# iorx65n register map
Registers are 8-bit, access not given, no defined reset value unless marked. A register's access mark holds for its fields unless they carry their own. Addresses are absolute; registers are grouped by the start of their names; [hi:lo] are bit positions; {n}, {i} and the like mark numbered series.

## SFR (part 7 of 7)
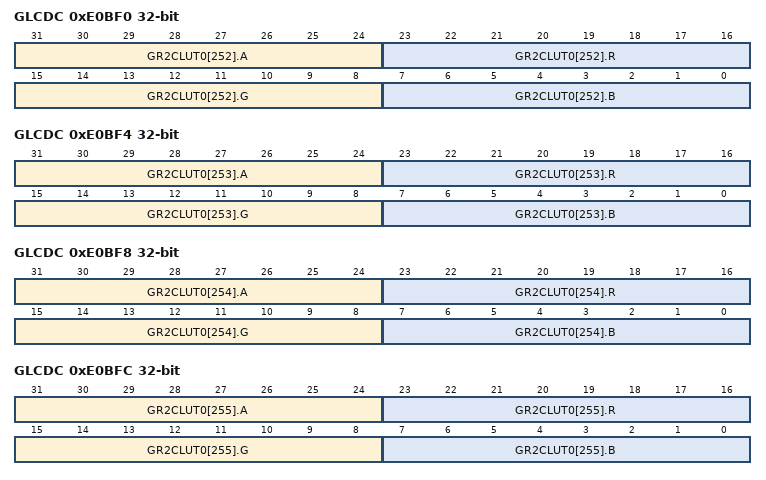
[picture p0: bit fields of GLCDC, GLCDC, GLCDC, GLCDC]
0xE0BF0 GLCDC 32-bit
  [31:24] GR2CLUT0[252].A, [23:16] GR2CLUT0[252].R, [15:8] GR2CLUT0[252].G, [7:0] GR2CLUT0[252].B
0xE0BF4 GLCDC 32-bit
  [31:24] GR2CLUT0[253].A, [23:16] GR2CLUT0[253].R, [15:8] GR2CLUT0[253].G, [7:0] GR2CLUT0[253].B
0xE0BF8 GLCDC 32-bit
  [31:24] GR2CLUT0[254].A, [23:16] GR2CLUT0[254].R, [15:8] GR2CLUT0[254].G, [7:0] GR2CLUT0[254].B
0xE0BFC GLCDC 32-bit
  [31:24] GR2CLUT0[255].A, [23:16] GR2CLUT0[255].R, [15:8] GR2CLUT0[255].G, [7:0] GR2CLUT0[255].B
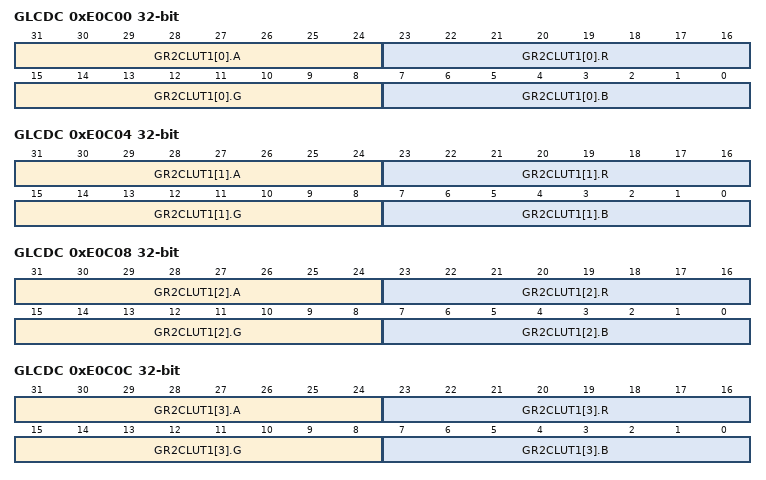
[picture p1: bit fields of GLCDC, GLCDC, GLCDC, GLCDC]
0xE0C00 GLCDC 32-bit
  [31:24] GR2CLUT1[0].A, [23:16] GR2CLUT1[0].R, [15:8] GR2CLUT1[0].G, [7:0] GR2CLUT1[0].B
0xE0C04 GLCDC 32-bit
  [31:24] GR2CLUT1[1].A, [23:16] GR2CLUT1[1].R, [15:8] GR2CLUT1[1].G, [7:0] GR2CLUT1[1].B
0xE0C08 GLCDC 32-bit
  [31:24] GR2CLUT1[2].A, [23:16] GR2CLUT1[2].R, [15:8] GR2CLUT1[2].G, [7:0] GR2CLUT1[2].B
0xE0C0C GLCDC 32-bit
  [31:24] GR2CLUT1[3].A, [23:16] GR2CLUT1[3].R, [15:8] GR2CLUT1[3].G, [7:0] GR2CLUT1[3].B
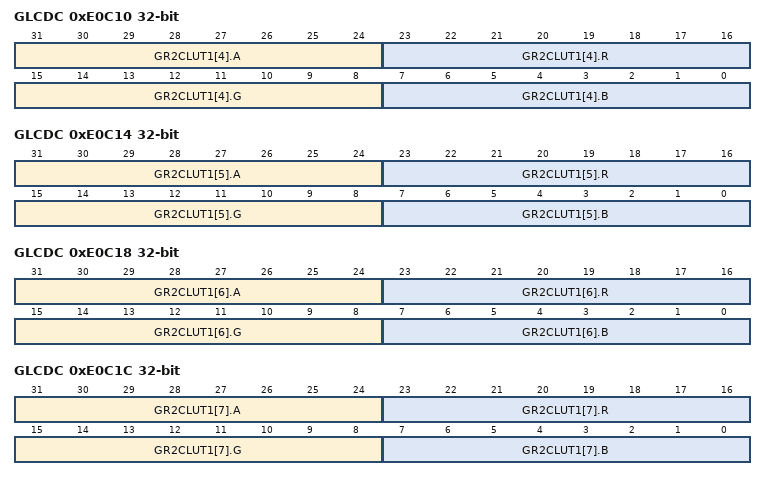
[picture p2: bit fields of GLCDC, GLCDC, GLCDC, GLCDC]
0xE0C10 GLCDC 32-bit
  [31:24] GR2CLUT1[4].A, [23:16] GR2CLUT1[4].R, [15:8] GR2CLUT1[4].G, [7:0] GR2CLUT1[4].B
0xE0C14 GLCDC 32-bit
  [31:24] GR2CLUT1[5].A, [23:16] GR2CLUT1[5].R, [15:8] GR2CLUT1[5].G, [7:0] GR2CLUT1[5].B
0xE0C18 GLCDC 32-bit
  [31:24] GR2CLUT1[6].A, [23:16] GR2CLUT1[6].R, [15:8] GR2CLUT1[6].G, [7:0] GR2CLUT1[6].B
0xE0C1C GLCDC 32-bit
  [31:24] GR2CLUT1[7].A, [23:16] GR2CLUT1[7].R, [15:8] GR2CLUT1[7].G, [7:0] GR2CLUT1[7].B
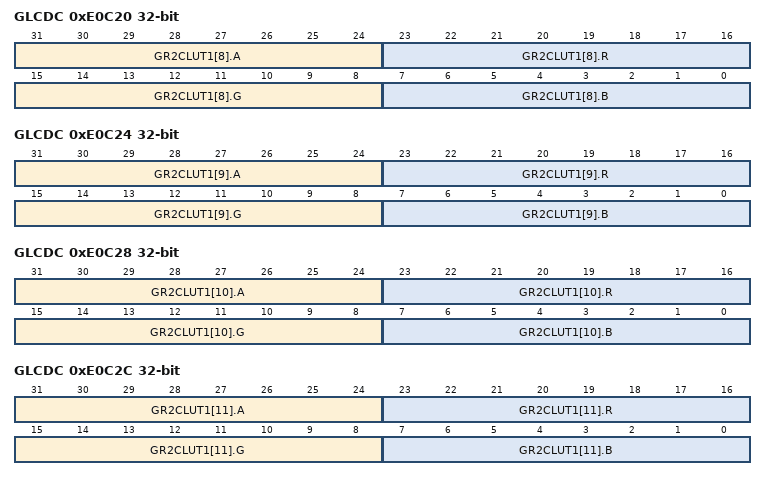
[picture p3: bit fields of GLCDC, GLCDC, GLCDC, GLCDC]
0xE0C20 GLCDC 32-bit
  [31:24] GR2CLUT1[8].A, [23:16] GR2CLUT1[8].R, [15:8] GR2CLUT1[8].G, [7:0] GR2CLUT1[8].B
0xE0C24 GLCDC 32-bit
  [31:24] GR2CLUT1[9].A, [23:16] GR2CLUT1[9].R, [15:8] GR2CLUT1[9].G, [7:0] GR2CLUT1[9].B
0xE0C28 GLCDC 32-bit
  [31:24] GR2CLUT1[10].A, [23:16] GR2CLUT1[10].R, [15:8] GR2CLUT1[10].G, [7:0] GR2CLUT1[10].B
0xE0C2C GLCDC 32-bit
  [31:24] GR2CLUT1[11].A, [23:16] GR2CLUT1[11].R, [15:8] GR2CLUT1[11].G, [7:0] GR2CLUT1[11].B
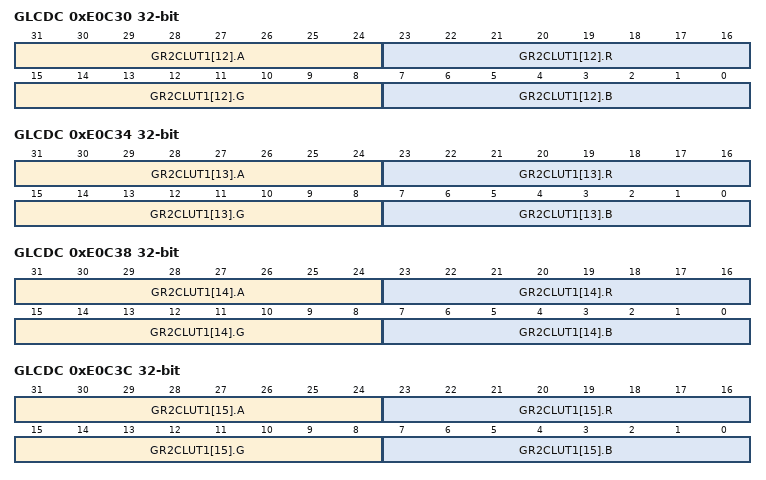
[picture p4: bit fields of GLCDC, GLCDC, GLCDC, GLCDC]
0xE0C30 GLCDC 32-bit
  [31:24] GR2CLUT1[12].A, [23:16] GR2CLUT1[12].R, [15:8] GR2CLUT1[12].G, [7:0] GR2CLUT1[12].B
0xE0C34 GLCDC 32-bit
  [31:24] GR2CLUT1[13].A, [23:16] GR2CLUT1[13].R, [15:8] GR2CLUT1[13].G, [7:0] GR2CLUT1[13].B
0xE0C38 GLCDC 32-bit
  [31:24] GR2CLUT1[14].A, [23:16] GR2CLUT1[14].R, [15:8] GR2CLUT1[14].G, [7:0] GR2CLUT1[14].B
0xE0C3C GLCDC 32-bit
  [31:24] GR2CLUT1[15].A, [23:16] GR2CLUT1[15].R, [15:8] GR2CLUT1[15].G, [7:0] GR2CLUT1[15].B
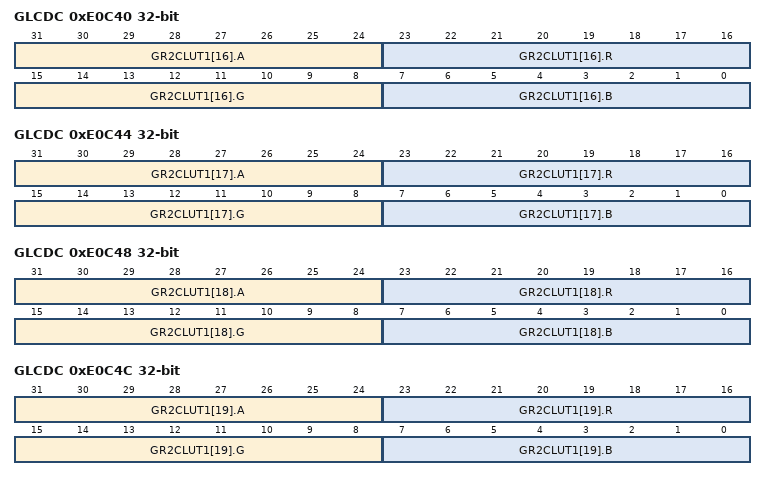
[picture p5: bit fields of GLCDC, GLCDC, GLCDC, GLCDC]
0xE0C40 GLCDC 32-bit
  [31:24] GR2CLUT1[16].A, [23:16] GR2CLUT1[16].R, [15:8] GR2CLUT1[16].G, [7:0] GR2CLUT1[16].B
0xE0C44 GLCDC 32-bit
  [31:24] GR2CLUT1[17].A, [23:16] GR2CLUT1[17].R, [15:8] GR2CLUT1[17].G, [7:0] GR2CLUT1[17].B
0xE0C48 GLCDC 32-bit
  [31:24] GR2CLUT1[18].A, [23:16] GR2CLUT1[18].R, [15:8] GR2CLUT1[18].G, [7:0] GR2CLUT1[18].B
0xE0C4C GLCDC 32-bit
  [31:24] GR2CLUT1[19].A, [23:16] GR2CLUT1[19].R, [15:8] GR2CLUT1[19].G, [7:0] GR2CLUT1[19].B
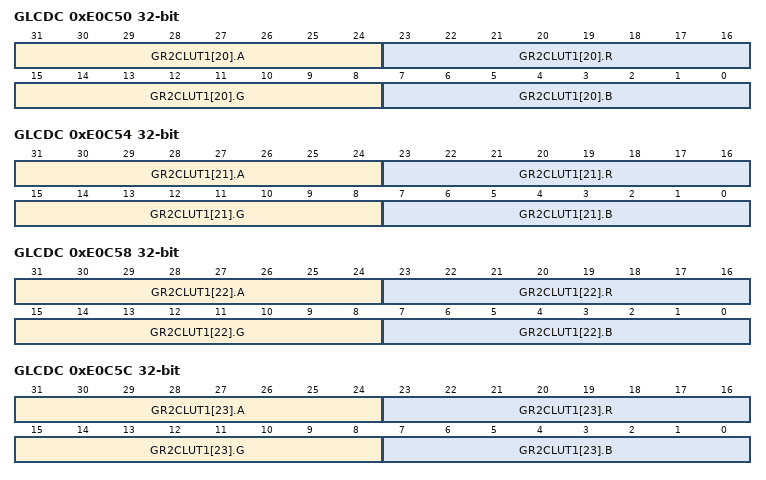
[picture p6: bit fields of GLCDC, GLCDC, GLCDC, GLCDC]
0xE0C50 GLCDC 32-bit
  [31:24] GR2CLUT1[20].A, [23:16] GR2CLUT1[20].R, [15:8] GR2CLUT1[20].G, [7:0] GR2CLUT1[20].B
0xE0C54 GLCDC 32-bit
  [31:24] GR2CLUT1[21].A, [23:16] GR2CLUT1[21].R, [15:8] GR2CLUT1[21].G, [7:0] GR2CLUT1[21].B
0xE0C58 GLCDC 32-bit
  [31:24] GR2CLUT1[22].A, [23:16] GR2CLUT1[22].R, [15:8] GR2CLUT1[22].G, [7:0] GR2CLUT1[22].B
0xE0C5C GLCDC 32-bit
  [31:24] GR2CLUT1[23].A, [23:16] GR2CLUT1[23].R, [15:8] GR2CLUT1[23].G, [7:0] GR2CLUT1[23].B
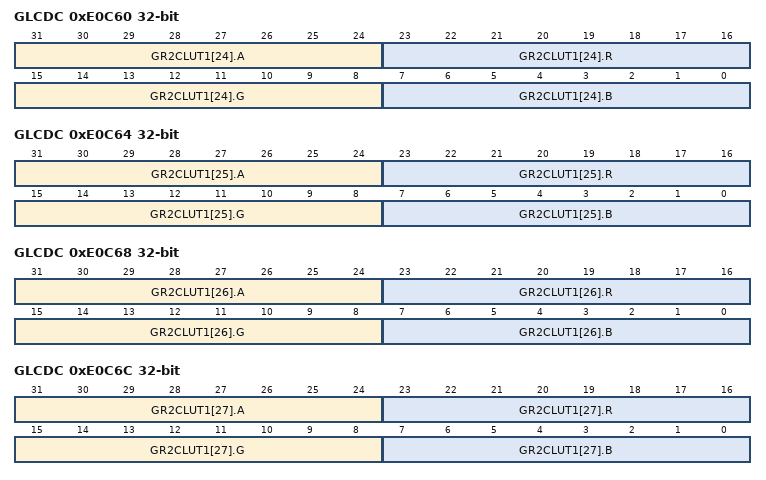
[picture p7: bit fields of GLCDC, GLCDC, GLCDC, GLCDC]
0xE0C60 GLCDC 32-bit
  [31:24] GR2CLUT1[24].A, [23:16] GR2CLUT1[24].R, [15:8] GR2CLUT1[24].G, [7:0] GR2CLUT1[24].B
0xE0C64 GLCDC 32-bit
  [31:24] GR2CLUT1[25].A, [23:16] GR2CLUT1[25].R, [15:8] GR2CLUT1[25].G, [7:0] GR2CLUT1[25].B
0xE0C68 GLCDC 32-bit
  [31:24] GR2CLUT1[26].A, [23:16] GR2CLUT1[26].R, [15:8] GR2CLUT1[26].G, [7:0] GR2CLUT1[26].B
0xE0C6C GLCDC 32-bit
  [31:24] GR2CLUT1[27].A, [23:16] GR2CLUT1[27].R, [15:8] GR2CLUT1[27].G, [7:0] GR2CLUT1[27].B
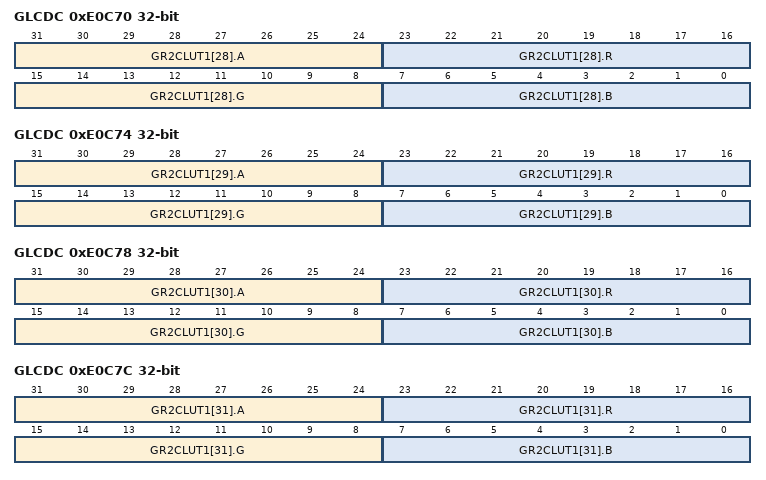
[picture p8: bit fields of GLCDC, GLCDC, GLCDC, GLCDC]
0xE0C70 GLCDC 32-bit
  [31:24] GR2CLUT1[28].A, [23:16] GR2CLUT1[28].R, [15:8] GR2CLUT1[28].G, [7:0] GR2CLUT1[28].B
0xE0C74 GLCDC 32-bit
  [31:24] GR2CLUT1[29].A, [23:16] GR2CLUT1[29].R, [15:8] GR2CLUT1[29].G, [7:0] GR2CLUT1[29].B
0xE0C78 GLCDC 32-bit
  [31:24] GR2CLUT1[30].A, [23:16] GR2CLUT1[30].R, [15:8] GR2CLUT1[30].G, [7:0] GR2CLUT1[30].B
0xE0C7C GLCDC 32-bit
  [31:24] GR2CLUT1[31].A, [23:16] GR2CLUT1[31].R, [15:8] GR2CLUT1[31].G, [7:0] GR2CLUT1[31].B
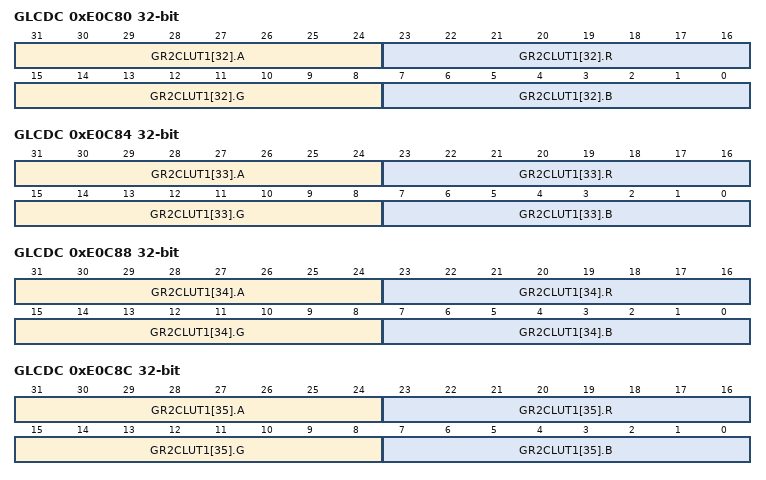
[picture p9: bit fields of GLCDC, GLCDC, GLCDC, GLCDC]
0xE0C80 GLCDC 32-bit
  [31:24] GR2CLUT1[32].A, [23:16] GR2CLUT1[32].R, [15:8] GR2CLUT1[32].G, [7:0] GR2CLUT1[32].B
0xE0C84 GLCDC 32-bit
  [31:24] GR2CLUT1[33].A, [23:16] GR2CLUT1[33].R, [15:8] GR2CLUT1[33].G, [7:0] GR2CLUT1[33].B
0xE0C88 GLCDC 32-bit
  [31:24] GR2CLUT1[34].A, [23:16] GR2CLUT1[34].R, [15:8] GR2CLUT1[34].G, [7:0] GR2CLUT1[34].B
0xE0C8C GLCDC 32-bit
  [31:24] GR2CLUT1[35].A, [23:16] GR2CLUT1[35].R, [15:8] GR2CLUT1[35].G, [7:0] GR2CLUT1[35].B
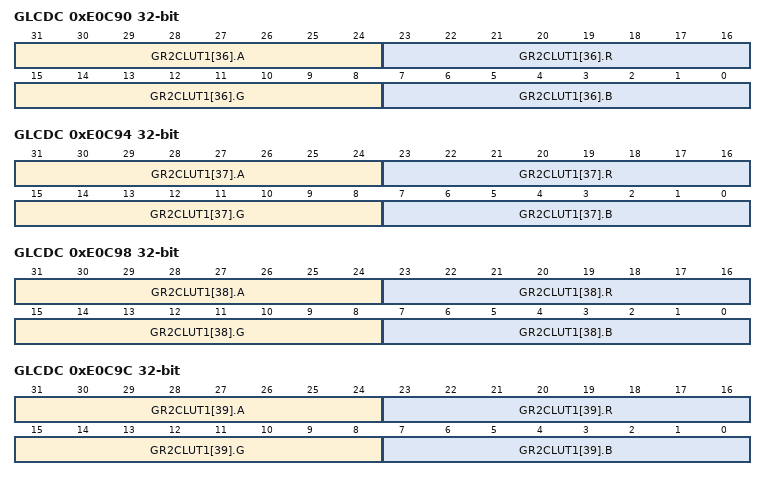
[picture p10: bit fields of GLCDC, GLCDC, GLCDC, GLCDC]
0xE0C90 GLCDC 32-bit
  [31:24] GR2CLUT1[36].A, [23:16] GR2CLUT1[36].R, [15:8] GR2CLUT1[36].G, [7:0] GR2CLUT1[36].B
0xE0C94 GLCDC 32-bit
  [31:24] GR2CLUT1[37].A, [23:16] GR2CLUT1[37].R, [15:8] GR2CLUT1[37].G, [7:0] GR2CLUT1[37].B
0xE0C98 GLCDC 32-bit
  [31:24] GR2CLUT1[38].A, [23:16] GR2CLUT1[38].R, [15:8] GR2CLUT1[38].G, [7:0] GR2CLUT1[38].B
0xE0C9C GLCDC 32-bit
  [31:24] GR2CLUT1[39].A, [23:16] GR2CLUT1[39].R, [15:8] GR2CLUT1[39].G, [7:0] GR2CLUT1[39].B
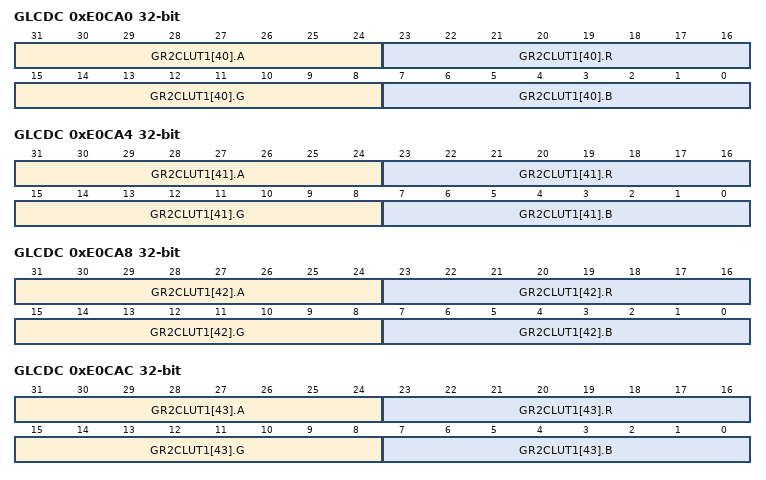
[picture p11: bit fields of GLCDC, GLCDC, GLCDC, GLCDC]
0xE0CA0 GLCDC 32-bit
  [31:24] GR2CLUT1[40].A, [23:16] GR2CLUT1[40].R, [15:8] GR2CLUT1[40].G, [7:0] GR2CLUT1[40].B
0xE0CA4 GLCDC 32-bit
  [31:24] GR2CLUT1[41].A, [23:16] GR2CLUT1[41].R, [15:8] GR2CLUT1[41].G, [7:0] GR2CLUT1[41].B
0xE0CA8 GLCDC 32-bit
  [31:24] GR2CLUT1[42].A, [23:16] GR2CLUT1[42].R, [15:8] GR2CLUT1[42].G, [7:0] GR2CLUT1[42].B
0xE0CAC GLCDC 32-bit
  [31:24] GR2CLUT1[43].A, [23:16] GR2CLUT1[43].R, [15:8] GR2CLUT1[43].G, [7:0] GR2CLUT1[43].B
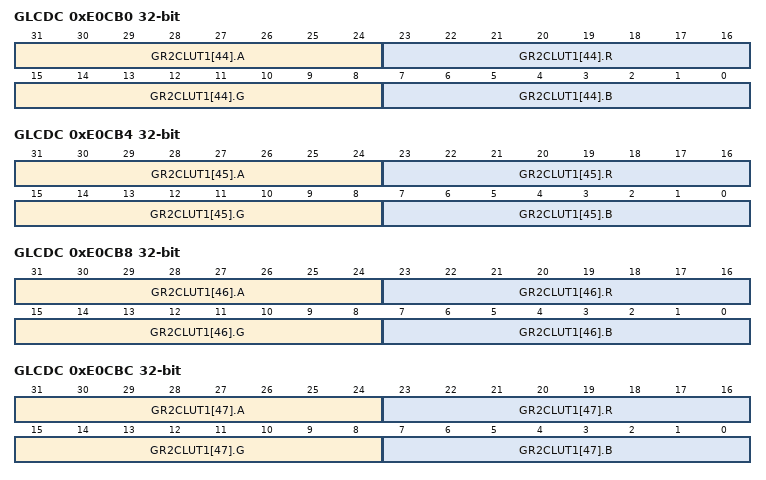
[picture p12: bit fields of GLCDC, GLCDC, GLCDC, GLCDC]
0xE0CB0 GLCDC 32-bit
  [31:24] GR2CLUT1[44].A, [23:16] GR2CLUT1[44].R, [15:8] GR2CLUT1[44].G, [7:0] GR2CLUT1[44].B
0xE0CB4 GLCDC 32-bit
  [31:24] GR2CLUT1[45].A, [23:16] GR2CLUT1[45].R, [15:8] GR2CLUT1[45].G, [7:0] GR2CLUT1[45].B
0xE0CB8 GLCDC 32-bit
  [31:24] GR2CLUT1[46].A, [23:16] GR2CLUT1[46].R, [15:8] GR2CLUT1[46].G, [7:0] GR2CLUT1[46].B
0xE0CBC GLCDC 32-bit
  [31:24] GR2CLUT1[47].A, [23:16] GR2CLUT1[47].R, [15:8] GR2CLUT1[47].G, [7:0] GR2CLUT1[47].B
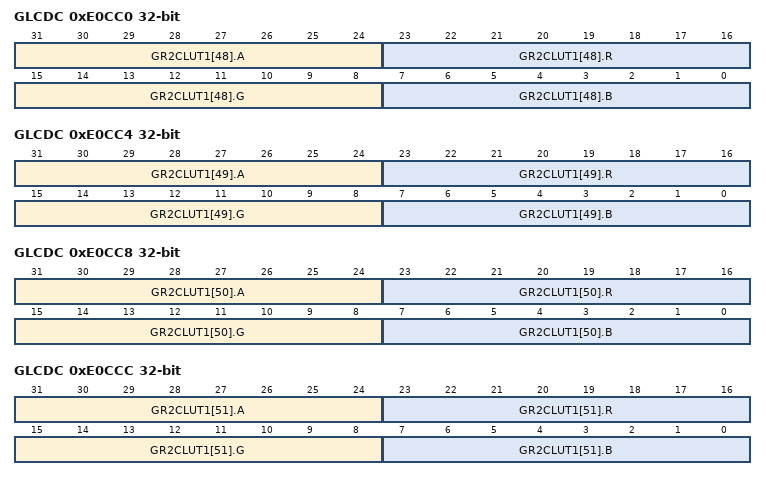
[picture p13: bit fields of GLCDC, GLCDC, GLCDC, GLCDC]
0xE0CC0 GLCDC 32-bit
  [31:24] GR2CLUT1[48].A, [23:16] GR2CLUT1[48].R, [15:8] GR2CLUT1[48].G, [7:0] GR2CLUT1[48].B
0xE0CC4 GLCDC 32-bit
  [31:24] GR2CLUT1[49].A, [23:16] GR2CLUT1[49].R, [15:8] GR2CLUT1[49].G, [7:0] GR2CLUT1[49].B
0xE0CC8 GLCDC 32-bit
  [31:24] GR2CLUT1[50].A, [23:16] GR2CLUT1[50].R, [15:8] GR2CLUT1[50].G, [7:0] GR2CLUT1[50].B
0xE0CCC GLCDC 32-bit
  [31:24] GR2CLUT1[51].A, [23:16] GR2CLUT1[51].R, [15:8] GR2CLUT1[51].G, [7:0] GR2CLUT1[51].B
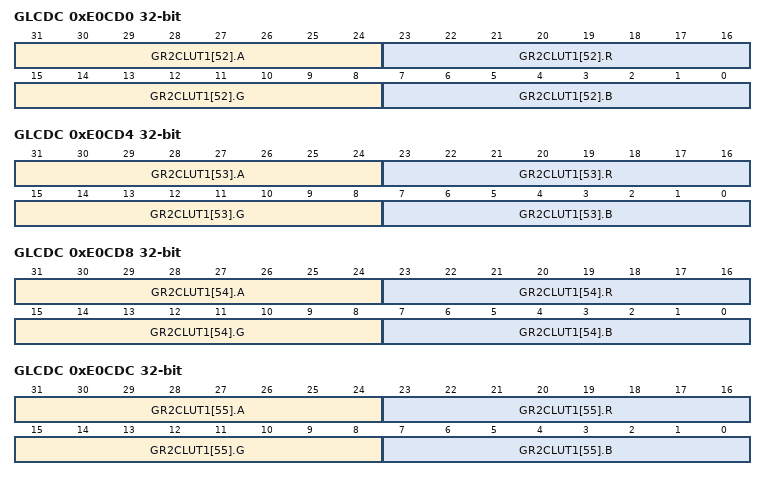
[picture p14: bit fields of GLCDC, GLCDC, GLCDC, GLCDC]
0xE0CD0 GLCDC 32-bit
  [31:24] GR2CLUT1[52].A, [23:16] GR2CLUT1[52].R, [15:8] GR2CLUT1[52].G, [7:0] GR2CLUT1[52].B
0xE0CD4 GLCDC 32-bit
  [31:24] GR2CLUT1[53].A, [23:16] GR2CLUT1[53].R, [15:8] GR2CLUT1[53].G, [7:0] GR2CLUT1[53].B
0xE0CD8 GLCDC 32-bit
  [31:24] GR2CLUT1[54].A, [23:16] GR2CLUT1[54].R, [15:8] GR2CLUT1[54].G, [7:0] GR2CLUT1[54].B
0xE0CDC GLCDC 32-bit
  [31:24] GR2CLUT1[55].A, [23:16] GR2CLUT1[55].R, [15:8] GR2CLUT1[55].G, [7:0] GR2CLUT1[55].B
0xE0CE0 GLCDC 32-bit
  [31:24] GR2CLUT1[56].A, [23:16] GR2CLUT1[56].R, [15:8] GR2CLUT1[56].G, [7:0] GR2CLUT1[56].B
0xE0CE4 GLCDC 32-bit
  [31:24] GR2CLUT1[57].A, [23:16] GR2CLUT1[57].R, [15:8] GR2CLUT1[57].G, [7:0] GR2CLUT1[57].B
0xE0CE8 GLCDC 32-bit
  [31:24] GR2CLUT1[58].A, [23:16] GR2CLUT1[58].R, [15:8] GR2CLUT1[58].G, [7:0] GR2CLUT1[58].B
0xE0CEC GLCDC 32-bit
  [31:24] GR2CLUT1[59].A, [23:16] GR2CLUT1[59].R, [15:8] GR2CLUT1[59].G, [7:0] GR2CLUT1[59].B
0xE0CF0 GLCDC 32-bit
  [31:24] GR2CLUT1[60].A, [23:16] GR2CLUT1[60].R, [15:8] GR2CLUT1[60].G, [7:0] GR2CLUT1[60].B
0xE0CF4 GLCDC 32-bit
  [31:24] GR2CLUT1[61].A, [23:16] GR2CLUT1[61].R, [15:8] GR2CLUT1[61].G, [7:0] GR2CLUT1[61].B
0xE0CF8 GLCDC 32-bit
  [31:24] GR2CLUT1[62].A, [23:16] GR2CLUT1[62].R, [15:8] GR2CLUT1[62].G, [7:0] GR2CLUT1[62].B
0xE0CFC GLCDC 32-bit
  [31:24] GR2CLUT1[63].A, [23:16] GR2CLUT1[63].R, [15:8] GR2CLUT1[63].G, [7:0] GR2CLUT1[63].B
0xE0D00 GLCDC 32-bit
  [31:24] GR2CLUT1[64].A, [23:16] GR2CLUT1[64].R, [15:8] GR2CLUT1[64].G, [7:0] GR2CLUT1[64].B
0xE0D04 GLCDC 32-bit
  [31:24] GR2CLUT1[65].A, [23:16] GR2CLUT1[65].R, [15:8] GR2CLUT1[65].G, [7:0] GR2CLUT1[65].B
0xE0D08 GLCDC 32-bit
  [31:24] GR2CLUT1[66].A, [23:16] GR2CLUT1[66].R, [15:8] GR2CLUT1[66].G, [7:0] GR2CLUT1[66].B
0xE0D0C GLCDC 32-bit
  [31:24] GR2CLUT1[67].A, [23:16] GR2CLUT1[67].R, [15:8] GR2CLUT1[67].G, [7:0] GR2CLUT1[67].B
0xE0D10 GLCDC 32-bit
  [31:24] GR2CLUT1[68].A, [23:16] GR2CLUT1[68].R, [15:8] GR2CLUT1[68].G, [7:0] GR2CLUT1[68].B
0xE0D14 GLCDC 32-bit
  [31:24] GR2CLUT1[69].A, [23:16] GR2CLUT1[69].R, [15:8] GR2CLUT1[69].G, [7:0] GR2CLUT1[69].B
0xE0D18 GLCDC 32-bit
  [31:24] GR2CLUT1[70].A, [23:16] GR2CLUT1[70].R, [15:8] GR2CLUT1[70].G, [7:0] GR2CLUT1[70].B
0xE0D1C GLCDC 32-bit
  [31:24] GR2CLUT1[71].A, [23:16] GR2CLUT1[71].R, [15:8] GR2CLUT1[71].G, [7:0] GR2CLUT1[71].B
0xE0D20 GLCDC 32-bit
  [31:24] GR2CLUT1[72].A, [23:16] GR2CLUT1[72].R, [15:8] GR2CLUT1[72].G, [7:0] GR2CLUT1[72].B
0xE0D24 GLCDC 32-bit
  [31:24] GR2CLUT1[73].A, [23:16] GR2CLUT1[73].R, [15:8] GR2CLUT1[73].G, [7:0] GR2CLUT1[73].B
0xE0D28 GLCDC 32-bit
  [31:24] GR2CLUT1[74].A, [23:16] GR2CLUT1[74].R, [15:8] GR2CLUT1[74].G, [7:0] GR2CLUT1[74].B
0xE0D2C GLCDC 32-bit
  [31:24] GR2CLUT1[75].A, [23:16] GR2CLUT1[75].R, [15:8] GR2CLUT1[75].G, [7:0] GR2CLUT1[75].B
0xE0D30 GLCDC 32-bit
  [31:24] GR2CLUT1[76].A, [23:16] GR2CLUT1[76].R, [15:8] GR2CLUT1[76].G, [7:0] GR2CLUT1[76].B
0xE0D34 GLCDC 32-bit
  [31:24] GR2CLUT1[77].A, [23:16] GR2CLUT1[77].R, [15:8] GR2CLUT1[77].G, [7:0] GR2CLUT1[77].B
0xE0D38 GLCDC 32-bit
  [31:24] GR2CLUT1[78].A, [23:16] GR2CLUT1[78].R, [15:8] GR2CLUT1[78].G, [7:0] GR2CLUT1[78].B
0xE0D3C GLCDC 32-bit
  [31:24] GR2CLUT1[79].A, [23:16] GR2CLUT1[79].R, [15:8] GR2CLUT1[79].G, [7:0] GR2CLUT1[79].B
0xE0D40 GLCDC 32-bit
  [31:24] GR2CLUT1[80].A, [23:16] GR2CLUT1[80].R, [15:8] GR2CLUT1[80].G, [7:0] GR2CLUT1[80].B
0xE0D44 GLCDC 32-bit
  [31:24] GR2CLUT1[81].A, [23:16] GR2CLUT1[81].R, [15:8] GR2CLUT1[81].G, [7:0] GR2CLUT1[81].B
0xE0D48 GLCDC 32-bit
  [31:24] GR2CLUT1[82].A, [23:16] GR2CLUT1[82].R, [15:8] GR2CLUT1[82].G, [7:0] GR2CLUT1[82].B
0xE0D4C GLCDC 32-bit
  [31:24] GR2CLUT1[83].A, [23:16] GR2CLUT1[83].R, [15:8] GR2CLUT1[83].G, [7:0] GR2CLUT1[83].B
0xE0D50 GLCDC 32-bit
  [31:24] GR2CLUT1[84].A, [23:16] GR2CLUT1[84].R, [15:8] GR2CLUT1[84].G, [7:0] GR2CLUT1[84].B
0xE0D54 GLCDC 32-bit
  [31:24] GR2CLUT1[85].A, [23:16] GR2CLUT1[85].R, [15:8] GR2CLUT1[85].G, [7:0] GR2CLUT1[85].B
0xE0D58 GLCDC 32-bit
  [31:24] GR2CLUT1[86].A, [23:16] GR2CLUT1[86].R, [15:8] GR2CLUT1[86].G, [7:0] GR2CLUT1[86].B
0xE0D5C GLCDC 32-bit
  [31:24] GR2CLUT1[87].A, [23:16] GR2CLUT1[87].R, [15:8] GR2CLUT1[87].G, [7:0] GR2CLUT1[87].B
0xE0D60 GLCDC 32-bit
  [31:24] GR2CLUT1[88].A, [23:16] GR2CLUT1[88].R, [15:8] GR2CLUT1[88].G, [7:0] GR2CLUT1[88].B
0xE0D64 GLCDC 32-bit
  [31:24] GR2CLUT1[89].A, [23:16] GR2CLUT1[89].R, [15:8] GR2CLUT1[89].G, [7:0] GR2CLUT1[89].B
0xE0D68 GLCDC 32-bit
  [31:24] GR2CLUT1[90].A, [23:16] GR2CLUT1[90].R, [15:8] GR2CLUT1[90].G, [7:0] GR2CLUT1[90].B
0xE0D6C GLCDC 32-bit
  [31:24] GR2CLUT1[91].A, [23:16] GR2CLUT1[91].R, [15:8] GR2CLUT1[91].G, [7:0] GR2CLUT1[91].B
0xE0D70 GLCDC 32-bit
  [31:24] GR2CLUT1[92].A, [23:16] GR2CLUT1[92].R, [15:8] GR2CLUT1[92].G, [7:0] GR2CLUT1[92].B
0xE0D74 GLCDC 32-bit
  [31:24] GR2CLUT1[93].A, [23:16] GR2CLUT1[93].R, [15:8] GR2CLUT1[93].G, [7:0] GR2CLUT1[93].B
0xE0D78 GLCDC 32-bit
  [31:24] GR2CLUT1[94].A, [23:16] GR2CLUT1[94].R, [15:8] GR2CLUT1[94].G, [7:0] GR2CLUT1[94].B
0xE0D7C GLCDC 32-bit
  [31:24] GR2CLUT1[95].A, [23:16] GR2CLUT1[95].R, [15:8] GR2CLUT1[95].G, [7:0] GR2CLUT1[95].B
0xE0D80 GLCDC 32-bit
  [31:24] GR2CLUT1[96].A, [23:16] GR2CLUT1[96].R, [15:8] GR2CLUT1[96].G, [7:0] GR2CLUT1[96].B
0xE0D84 GLCDC 32-bit
  [31:24] GR2CLUT1[97].A, [23:16] GR2CLUT1[97].R, [15:8] GR2CLUT1[97].G, [7:0] GR2CLUT1[97].B
0xE0D88 GLCDC 32-bit
  [31:24] GR2CLUT1[98].A, [23:16] GR2CLUT1[98].R, [15:8] GR2CLUT1[98].G, [7:0] GR2CLUT1[98].B
0xE0D8C GLCDC 32-bit
  [31:24] GR2CLUT1[99].A, [23:16] GR2CLUT1[99].R, [15:8] GR2CLUT1[99].G, [7:0] GR2CLUT1[99].B
0xE0D90 GLCDC 32-bit
  [31:24] GR2CLUT1[100].A, [23:16] GR2CLUT1[100].R, [15:8] GR2CLUT1[100].G, [7:0] GR2CLUT1[100].B
0xE0D94 GLCDC 32-bit
  [31:24] GR2CLUT1[101].A, [23:16] GR2CLUT1[101].R, [15:8] GR2CLUT1[101].G, [7:0] GR2CLUT1[101].B
0xE0D98 GLCDC 32-bit
  [31:24] GR2CLUT1[102].A, [23:16] GR2CLUT1[102].R, [15:8] GR2CLUT1[102].G, [7:0] GR2CLUT1[102].B
0xE0D9C GLCDC 32-bit
  [31:24] GR2CLUT1[103].A, [23:16] GR2CLUT1[103].R, [15:8] GR2CLUT1[103].G, [7:0] GR2CLUT1[103].B
0xE0DA0 GLCDC 32-bit
  [31:24] GR2CLUT1[104].A, [23:16] GR2CLUT1[104].R, [15:8] GR2CLUT1[104].G, [7:0] GR2CLUT1[104].B
0xE0DA4 GLCDC 32-bit
  [31:24] GR2CLUT1[105].A, [23:16] GR2CLUT1[105].R, [15:8] GR2CLUT1[105].G, [7:0] GR2CLUT1[105].B
0xE0DA8 GLCDC 32-bit
  [31:24] GR2CLUT1[106].A, [23:16] GR2CLUT1[106].R, [15:8] GR2CLUT1[106].G, [7:0] GR2CLUT1[106].B
0xE0DAC GLCDC 32-bit
  [31:24] GR2CLUT1[107].A, [23:16] GR2CLUT1[107].R, [15:8] GR2CLUT1[107].G, [7:0] GR2CLUT1[107].B
0xE0DB0 GLCDC 32-bit
  [31:24] GR2CLUT1[108].A, [23:16] GR2CLUT1[108].R, [15:8] GR2CLUT1[108].G, [7:0] GR2CLUT1[108].B
0xE0DB4 GLCDC 32-bit
  [31:24] GR2CLUT1[109].A, [23:16] GR2CLUT1[109].R, [15:8] GR2CLUT1[109].G, [7:0] GR2CLUT1[109].B
0xE0DB8 GLCDC 32-bit
  [31:24] GR2CLUT1[110].A, [23:16] GR2CLUT1[110].R, [15:8] GR2CLUT1[110].G, [7:0] GR2CLUT1[110].B
0xE0DBC GLCDC 32-bit
  [31:24] GR2CLUT1[111].A, [23:16] GR2CLUT1[111].R, [15:8] GR2CLUT1[111].G, [7:0] GR2CLUT1[111].B
0xE0DC0 GLCDC 32-bit
  [31:24] GR2CLUT1[112].A, [23:16] GR2CLUT1[112].R, [15:8] GR2CLUT1[112].G, [7:0] GR2CLUT1[112].B
0xE0DC4 GLCDC 32-bit
  [31:24] GR2CLUT1[113].A, [23:16] GR2CLUT1[113].R, [15:8] GR2CLUT1[113].G, [7:0] GR2CLUT1[113].B
0xE0DC8 GLCDC 32-bit
  [31:24] GR2CLUT1[114].A, [23:16] GR2CLUT1[114].R, [15:8] GR2CLUT1[114].G, [7:0] GR2CLUT1[114].B
0xE0DCC GLCDC 32-bit
  [31:24] GR2CLUT1[115].A, [23:16] GR2CLUT1[115].R, [15:8] GR2CLUT1[115].G, [7:0] GR2CLUT1[115].B
0xE0DD0 GLCDC 32-bit
  [31:24] GR2CLUT1[116].A, [23:16] GR2CLUT1[116].R, [15:8] GR2CLUT1[116].G, [7:0] GR2CLUT1[116].B
0xE0DD4 GLCDC 32-bit
  [31:24] GR2CLUT1[117].A, [23:16] GR2CLUT1[117].R, [15:8] GR2CLUT1[117].G, [7:0] GR2CLUT1[117].B
0xE0DD8 GLCDC 32-bit
  [31:24] GR2CLUT1[118].A, [23:16] GR2CLUT1[118].R, [15:8] GR2CLUT1[118].G, [7:0] GR2CLUT1[118].B
0xE0DDC GLCDC 32-bit
  [31:24] GR2CLUT1[119].A, [23:16] GR2CLUT1[119].R, [15:8] GR2CLUT1[119].G, [7:0] GR2CLUT1[119].B
0xE0DE0 GLCDC 32-bit
  [31:24] GR2CLUT1[120].A, [23:16] GR2CLUT1[120].R, [15:8] GR2CLUT1[120].G, [7:0] GR2CLUT1[120].B
0xE0DE4 GLCDC 32-bit
  [31:24] GR2CLUT1[121].A, [23:16] GR2CLUT1[121].R, [15:8] GR2CLUT1[121].G, [7:0] GR2CLUT1[121].B
0xE0DE8 GLCDC 32-bit
  [31:24] GR2CLUT1[122].A, [23:16] GR2CLUT1[122].R, [15:8] GR2CLUT1[122].G, [7:0] GR2CLUT1[122].B
0xE0DEC GLCDC 32-bit
  [31:24] GR2CLUT1[123].A, [23:16] GR2CLUT1[123].R, [15:8] GR2CLUT1[123].G, [7:0] GR2CLUT1[123].B
0xE0DF0 GLCDC 32-bit
  [31:24] GR2CLUT1[124].A, [23:16] GR2CLUT1[124].R, [15:8] GR2CLUT1[124].G, [7:0] GR2CLUT1[124].B
0xE0DF4 GLCDC 32-bit
  [31:24] GR2CLUT1[125].A, [23:16] GR2CLUT1[125].R, [15:8] GR2CLUT1[125].G, [7:0] GR2CLUT1[125].B
0xE0DF8 GLCDC 32-bit
  [31:24] GR2CLUT1[126].A, [23:16] GR2CLUT1[126].R, [15:8] GR2CLUT1[126].G, [7:0] GR2CLUT1[126].B
0xE0DFC GLCDC 32-bit
  [31:24] GR2CLUT1[127].A, [23:16] GR2CLUT1[127].R, [15:8] GR2CLUT1[127].G, [7:0] GR2CLUT1[127].B
0xE0E00 GLCDC 32-bit
  [31:24] GR2CLUT1[128].A, [23:16] GR2CLUT1[128].R, [15:8] GR2CLUT1[128].G, [7:0] GR2CLUT1[128].B
0xE0E04 GLCDC 32-bit
  [31:24] GR2CLUT1[129].A, [23:16] GR2CLUT1[129].R, [15:8] GR2CLUT1[129].G, [7:0] GR2CLUT1[129].B
0xE0E08 GLCDC 32-bit
  [31:24] GR2CLUT1[130].A, [23:16] GR2CLUT1[130].R, [15:8] GR2CLUT1[130].G, [7:0] GR2CLUT1[130].B
0xE0E0C GLCDC 32-bit
  [31:24] GR2CLUT1[131].A, [23:16] GR2CLUT1[131].R, [15:8] GR2CLUT1[131].G, [7:0] GR2CLUT1[131].B
0xE0E10 GLCDC 32-bit
  [31:24] GR2CLUT1[132].A, [23:16] GR2CLUT1[132].R, [15:8] GR2CLUT1[132].G, [7:0] GR2CLUT1[132].B
0xE0E14 GLCDC 32-bit
  [31:24] GR2CLUT1[133].A, [23:16] GR2CLUT1[133].R, [15:8] GR2CLUT1[133].G, [7:0] GR2CLUT1[133].B
0xE0E18 GLCDC 32-bit
  [31:24] GR2CLUT1[134].A, [23:16] GR2CLUT1[134].R, [15:8] GR2CLUT1[134].G, [7:0] GR2CLUT1[134].B
0xE0E1C GLCDC 32-bit
  [31:24] GR2CLUT1[135].A, [23:16] GR2CLUT1[135].R, [15:8] GR2CLUT1[135].G, [7:0] GR2CLUT1[135].B
0xE0E20 GLCDC 32-bit
  [31:24] GR2CLUT1[136].A, [23:16] GR2CLUT1[136].R, [15:8] GR2CLUT1[136].G, [7:0] GR2CLUT1[136].B
0xE0E24 GLCDC 32-bit
  [31:24] GR2CLUT1[137].A, [23:16] GR2CLUT1[137].R, [15:8] GR2CLUT1[137].G, [7:0] GR2CLUT1[137].B
0xE0E28 GLCDC 32-bit
  [31:24] GR2CLUT1[138].A, [23:16] GR2CLUT1[138].R, [15:8] GR2CLUT1[138].G, [7:0] GR2CLUT1[138].B
0xE0E2C GLCDC 32-bit
  [31:24] GR2CLUT1[139].A, [23:16] GR2CLUT1[139].R, [15:8] GR2CLUT1[139].G, [7:0] GR2CLUT1[139].B
0xE0E30 GLCDC 32-bit
  [31:24] GR2CLUT1[140].A, [23:16] GR2CLUT1[140].R, [15:8] GR2CLUT1[140].G, [7:0] GR2CLUT1[140].B
0xE0E34 GLCDC 32-bit
  [31:24] GR2CLUT1[141].A, [23:16] GR2CLUT1[141].R, [15:8] GR2CLUT1[141].G, [7:0] GR2CLUT1[141].B
0xE0E38 GLCDC 32-bit
  [31:24] GR2CLUT1[142].A, [23:16] GR2CLUT1[142].R, [15:8] GR2CLUT1[142].G, [7:0] GR2CLUT1[142].B
0xE0E3C GLCDC 32-bit
  [31:24] GR2CLUT1[143].A, [23:16] GR2CLUT1[143].R, [15:8] GR2CLUT1[143].G, [7:0] GR2CLUT1[143].B
0xE0E40 GLCDC 32-bit
  [31:24] GR2CLUT1[144].A, [23:16] GR2CLUT1[144].R, [15:8] GR2CLUT1[144].G, [7:0] GR2CLUT1[144].B
0xE0E44 GLCDC 32-bit
  [31:24] GR2CLUT1[145].A, [23:16] GR2CLUT1[145].R, [15:8] GR2CLUT1[145].G, [7:0] GR2CLUT1[145].B
0xE0E48 GLCDC 32-bit
  [31:24] GR2CLUT1[146].A, [23:16] GR2CLUT1[146].R, [15:8] GR2CLUT1[146].G, [7:0] GR2CLUT1[146].B
0xE0E4C GLCDC 32-bit
  [31:24] GR2CLUT1[147].A, [23:16] GR2CLUT1[147].R, [15:8] GR2CLUT1[147].G, [7:0] GR2CLUT1[147].B
0xE0E50 GLCDC 32-bit
  [31:24] GR2CLUT1[148].A, [23:16] GR2CLUT1[148].R, [15:8] GR2CLUT1[148].G, [7:0] GR2CLUT1[148].B
0xE0E54 GLCDC 32-bit
  [31:24] GR2CLUT1[149].A, [23:16] GR2CLUT1[149].R, [15:8] GR2CLUT1[149].G, [7:0] GR2CLUT1[149].B
0xE0E58 GLCDC 32-bit
  [31:24] GR2CLUT1[150].A, [23:16] GR2CLUT1[150].R, [15:8] GR2CLUT1[150].G, [7:0] GR2CLUT1[150].B
0xE0E5C GLCDC 32-bit
  [31:24] GR2CLUT1[151].A, [23:16] GR2CLUT1[151].R, [15:8] GR2CLUT1[151].G, [7:0] GR2CLUT1[151].B
0xE0E60 GLCDC 32-bit
  [31:24] GR2CLUT1[152].A, [23:16] GR2CLUT1[152].R, [15:8] GR2CLUT1[152].G, [7:0] GR2CLUT1[152].B
0xE0E64 GLCDC 32-bit
  [31:24] GR2CLUT1[153].A, [23:16] GR2CLUT1[153].R, [15:8] GR2CLUT1[153].G, [7:0] GR2CLUT1[153].B
0xE0E68 GLCDC 32-bit
  [31:24] GR2CLUT1[154].A, [23:16] GR2CLUT1[154].R, [15:8] GR2CLUT1[154].G, [7:0] GR2CLUT1[154].B
0xE0E6C GLCDC 32-bit
  [31:24] GR2CLUT1[155].A, [23:16] GR2CLUT1[155].R, [15:8] GR2CLUT1[155].G, [7:0] GR2CLUT1[155].B
0xE0E70 GLCDC 32-bit
  [31:24] GR2CLUT1[156].A, [23:16] GR2CLUT1[156].R, [15:8] GR2CLUT1[156].G, [7:0] GR2CLUT1[156].B
0xE0E74 GLCDC 32-bit
  [31:24] GR2CLUT1[157].A, [23:16] GR2CLUT1[157].R, [15:8] GR2CLUT1[157].G, [7:0] GR2CLUT1[157].B
0xE0E78 GLCDC 32-bit
  [31:24] GR2CLUT1[158].A, [23:16] GR2CLUT1[158].R, [15:8] GR2CLUT1[158].G, [7:0] GR2CLUT1[158].B
0xE0E7C GLCDC 32-bit
  [31:24] GR2CLUT1[159].A, [23:16] GR2CLUT1[159].R, [15:8] GR2CLUT1[159].G, [7:0] GR2CLUT1[159].B
0xE0E80 GLCDC 32-bit
  [31:24] GR2CLUT1[160].A, [23:16] GR2CLUT1[160].R, [15:8] GR2CLUT1[160].G, [7:0] GR2CLUT1[160].B
0xE0E84 GLCDC 32-bit
  [31:24] GR2CLUT1[161].A, [23:16] GR2CLUT1[161].R, [15:8] GR2CLUT1[161].G, [7:0] GR2CLUT1[161].B
0xE0E88 GLCDC 32-bit
  [31:24] GR2CLUT1[162].A, [23:16] GR2CLUT1[162].R, [15:8] GR2CLUT1[162].G, [7:0] GR2CLUT1[162].B
0xE0E8C GLCDC 32-bit
  [31:24] GR2CLUT1[163].A, [23:16] GR2CLUT1[163].R, [15:8] GR2CLUT1[163].G, [7:0] GR2CLUT1[163].B
0xE0E90 GLCDC 32-bit
  [31:24] GR2CLUT1[164].A, [23:16] GR2CLUT1[164].R, [15:8] GR2CLUT1[164].G, [7:0] GR2CLUT1[164].B
0xE0E94 GLCDC 32-bit
  [31:24] GR2CLUT1[165].A, [23:16] GR2CLUT1[165].R, [15:8] GR2CLUT1[165].G, [7:0] GR2CLUT1[165].B
0xE0E98 GLCDC 32-bit
  [31:24] GR2CLUT1[166].A, [23:16] GR2CLUT1[166].R, [15:8] GR2CLUT1[166].G, [7:0] GR2CLUT1[166].B
0xE0E9C GLCDC 32-bit
  [31:24] GR2CLUT1[167].A, [23:16] GR2CLUT1[167].R, [15:8] GR2CLUT1[167].G, [7:0] GR2CLUT1[167].B
0xE0EA0 GLCDC 32-bit
  [31:24] GR2CLUT1[168].A, [23:16] GR2CLUT1[168].R, [15:8] GR2CLUT1[168].G, [7:0] GR2CLUT1[168].B
0xE0EA4 GLCDC 32-bit
  [31:24] GR2CLUT1[169].A, [23:16] GR2CLUT1[169].R, [15:8] GR2CLUT1[169].G, [7:0] GR2CLUT1[169].B
0xE0EA8 GLCDC 32-bit
  [31:24] GR2CLUT1[170].A, [23:16] GR2CLUT1[170].R, [15:8] GR2CLUT1[170].G, [7:0] GR2CLUT1[170].B
0xE0EAC GLCDC 32-bit
  [31:24] GR2CLUT1[171].A, [23:16] GR2CLUT1[171].R, [15:8] GR2CLUT1[171].G, [7:0] GR2CLUT1[171].B
0xE0EB0 GLCDC 32-bit
  [31:24] GR2CLUT1[172].A, [23:16] GR2CLUT1[172].R, [15:8] GR2CLUT1[172].G, [7:0] GR2CLUT1[172].B
0xE0EB4 GLCDC 32-bit
  [31:24] GR2CLUT1[173].A, [23:16] GR2CLUT1[173].R, [15:8] GR2CLUT1[173].G, [7:0] GR2CLUT1[173].B
0xE0EB8 GLCDC 32-bit
  [31:24] GR2CLUT1[174].A, [23:16] GR2CLUT1[174].R, [15:8] GR2CLUT1[174].G, [7:0] GR2CLUT1[174].B
0xE0EBC GLCDC 32-bit
  [31:24] GR2CLUT1[175].A, [23:16] GR2CLUT1[175].R, [15:8] GR2CLUT1[175].G, [7:0] GR2CLUT1[175].B
0xE0EC0 GLCDC 32-bit
  [31:24] GR2CLUT1[176].A, [23:16] GR2CLUT1[176].R, [15:8] GR2CLUT1[176].G, [7:0] GR2CLUT1[176].B
0xE0EC4 GLCDC 32-bit
  [31:24] GR2CLUT1[177].A, [23:16] GR2CLUT1[177].R, [15:8] GR2CLUT1[177].G, [7:0] GR2CLUT1[177].B
0xE0EC8 GLCDC 32-bit
  [31:24] GR2CLUT1[178].A, [23:16] GR2CLUT1[178].R, [15:8] GR2CLUT1[178].G, [7:0] GR2CLUT1[178].B
0xE0ECC GLCDC 32-bit
  [31:24] GR2CLUT1[179].A, [23:16] GR2CLUT1[179].R, [15:8] GR2CLUT1[179].G, [7:0] GR2CLUT1[179].B
0xE0ED0 GLCDC 32-bit
  [31:24] GR2CLUT1[180].A, [23:16] GR2CLUT1[180].R, [15:8] GR2CLUT1[180].G, [7:0] GR2CLUT1[180].B
0xE0ED4 GLCDC 32-bit
  [31:24] GR2CLUT1[181].A, [23:16] GR2CLUT1[181].R, [15:8] GR2CLUT1[181].G, [7:0] GR2CLUT1[181].B
0xE0ED8 GLCDC 32-bit
  [31:24] GR2CLUT1[182].A, [23:16] GR2CLUT1[182].R, [15:8] GR2CLUT1[182].G, [7:0] GR2CLUT1[182].B
0xE0EDC GLCDC 32-bit
  [31:24] GR2CLUT1[183].A, [23:16] GR2CLUT1[183].R, [15:8] GR2CLUT1[183].G, [7:0] GR2CLUT1[183].B
0xE0EE0 GLCDC 32-bit
  [31:24] GR2CLUT1[184].A, [23:16] GR2CLUT1[184].R, [15:8] GR2CLUT1[184].G, [7:0] GR2CLUT1[184].B
0xE0EE4 GLCDC 32-bit
  [31:24] GR2CLUT1[185].A, [23:16] GR2CLUT1[185].R, [15:8] GR2CLUT1[185].G, [7:0] GR2CLUT1[185].B
0xE0EE8 GLCDC 32-bit
  [31:24] GR2CLUT1[186].A, [23:16] GR2CLUT1[186].R, [15:8] GR2CLUT1[186].G, [7:0] GR2CLUT1[186].B
0xE0EEC GLCDC 32-bit
  [31:24] GR2CLUT1[187].A, [23:16] GR2CLUT1[187].R, [15:8] GR2CLUT1[187].G, [7:0] GR2CLUT1[187].B
0xE0EF0 GLCDC 32-bit
  [31:24] GR2CLUT1[188].A, [23:16] GR2CLUT1[188].R, [15:8] GR2CLUT1[188].G, [7:0] GR2CLUT1[188].B
0xE0EF4 GLCDC 32-bit
  [31:24] GR2CLUT1[189].A, [23:16] GR2CLUT1[189].R, [15:8] GR2CLUT1[189].G, [7:0] GR2CLUT1[189].B
0xE0EF8 GLCDC 32-bit
  [31:24] GR2CLUT1[190].A, [23:16] GR2CLUT1[190].R, [15:8] GR2CLUT1[190].G, [7:0] GR2CLUT1[190].B
0xE0EFC GLCDC 32-bit
  [31:24] GR2CLUT1[191].A, [23:16] GR2CLUT1[191].R, [15:8] GR2CLUT1[191].G, [7:0] GR2CLUT1[191].B
0xE0F00 GLCDC 32-bit
  [31:24] GR2CLUT1[192].A, [23:16] GR2CLUT1[192].R, [15:8] GR2CLUT1[192].G, [7:0] GR2CLUT1[192].B
0xE0F04 GLCDC 32-bit
  [31:24] GR2CLUT1[193].A, [23:16] GR2CLUT1[193].R, [15:8] GR2CLUT1[193].G, [7:0] GR2CLUT1[193].B
0xE0F08 GLCDC 32-bit
  [31:24] GR2CLUT1[194].A, [23:16] GR2CLUT1[194].R, [15:8] GR2CLUT1[194].G, [7:0] GR2CLUT1[194].B
0xE0F0C GLCDC 32-bit
  [31:24] GR2CLUT1[195].A, [23:16] GR2CLUT1[195].R, [15:8] GR2CLUT1[195].G, [7:0] GR2CLUT1[195].B
0xE0F10 GLCDC 32-bit
  [31:24] GR2CLUT1[196].A, [23:16] GR2CLUT1[196].R, [15:8] GR2CLUT1[196].G, [7:0] GR2CLUT1[196].B
0xE0F14 GLCDC 32-bit
  [31:24] GR2CLUT1[197].A, [23:16] GR2CLUT1[197].R, [15:8] GR2CLUT1[197].G, [7:0] GR2CLUT1[197].B
0xE0F18 GLCDC 32-bit
  [31:24] GR2CLUT1[198].A, [23:16] GR2CLUT1[198].R, [15:8] GR2CLUT1[198].G, [7:0] GR2CLUT1[198].B
0xE0F1C GLCDC 32-bit
  [31:24] GR2CLUT1[199].A, [23:16] GR2CLUT1[199].R, [15:8] GR2CLUT1[199].G, [7:0] GR2CLUT1[199].B
0xE0F20 GLCDC 32-bit
  [31:24] GR2CLUT1[200].A, [23:16] GR2CLUT1[200].R, [15:8] GR2CLUT1[200].G, [7:0] GR2CLUT1[200].B
0xE0F24 GLCDC 32-bit
  [31:24] GR2CLUT1[201].A, [23:16] GR2CLUT1[201].R, [15:8] GR2CLUT1[201].G, [7:0] GR2CLUT1[201].B
0xE0F28 GLCDC 32-bit
  [31:24] GR2CLUT1[202].A, [23:16] GR2CLUT1[202].R, [15:8] GR2CLUT1[202].G, [7:0] GR2CLUT1[202].B
0xE0F2C GLCDC 32-bit
  [31:24] GR2CLUT1[203].A, [23:16] GR2CLUT1[203].R, [15:8] GR2CLUT1[203].G, [7:0] GR2CLUT1[203].B
0xE0F30 GLCDC 32-bit
  [31:24] GR2CLUT1[204].A, [23:16] GR2CLUT1[204].R, [15:8] GR2CLUT1[204].G, [7:0] GR2CLUT1[204].B
0xE0F34 GLCDC 32-bit
  [31:24] GR2CLUT1[205].A, [23:16] GR2CLUT1[205].R, [15:8] GR2CLUT1[205].G, [7:0] GR2CLUT1[205].B
0xE0F38 GLCDC 32-bit
  [31:24] GR2CLUT1[206].A, [23:16] GR2CLUT1[206].R, [15:8] GR2CLUT1[206].G, [7:0] GR2CLUT1[206].B
0xE0F3C GLCDC 32-bit
  [31:24] GR2CLUT1[207].A, [23:16] GR2CLUT1[207].R, [15:8] GR2CLUT1[207].G, [7:0] GR2CLUT1[207].B
0xE0F40 GLCDC 32-bit
  [31:24] GR2CLUT1[208].A, [23:16] GR2CLUT1[208].R, [15:8] GR2CLUT1[208].G, [7:0] GR2CLUT1[208].B
0xE0F44 GLCDC 32-bit
  [31:24] GR2CLUT1[209].A, [23:16] GR2CLUT1[209].R, [15:8] GR2CLUT1[209].G, [7:0] GR2CLUT1[209].B
0xE0F48 GLCDC 32-bit
  [31:24] GR2CLUT1[210].A, [23:16] GR2CLUT1[210].R, [15:8] GR2CLUT1[210].G, [7:0] GR2CLUT1[210].B
0xE0F4C GLCDC 32-bit
  [31:24] GR2CLUT1[211].A, [23:16] GR2CLUT1[211].R, [15:8] GR2CLUT1[211].G, [7:0] GR2CLUT1[211].B
0xE0F50 GLCDC 32-bit
  [31:24] GR2CLUT1[212].A, [23:16] GR2CLUT1[212].R, [15:8] GR2CLUT1[212].G, [7:0] GR2CLUT1[212].B
0xE0F54 GLCDC 32-bit
  [31:24] GR2CLUT1[213].A, [23:16] GR2CLUT1[213].R, [15:8] GR2CLUT1[213].G, [7:0] GR2CLUT1[213].B
0xE0F58 GLCDC 32-bit
  [31:24] GR2CLUT1[214].A, [23:16] GR2CLUT1[214].R, [15:8] GR2CLUT1[214].G, [7:0] GR2CLUT1[214].B
0xE0F5C GLCDC 32-bit
  [31:24] GR2CLUT1[215].A, [23:16] GR2CLUT1[215].R, [15:8] GR2CLUT1[215].G, [7:0] GR2CLUT1[215].B
0xE0F60 GLCDC 32-bit
  [31:24] GR2CLUT1[216].A, [23:16] GR2CLUT1[216].R, [15:8] GR2CLUT1[216].G, [7:0] GR2CLUT1[216].B
0xE0F64 GLCDC 32-bit
  [31:24] GR2CLUT1[217].A, [23:16] GR2CLUT1[217].R, [15:8] GR2CLUT1[217].G, [7:0] GR2CLUT1[217].B
0xE0F68 GLCDC 32-bit
  [31:24] GR2CLUT1[218].A, [23:16] GR2CLUT1[218].R, [15:8] GR2CLUT1[218].G, [7:0] GR2CLUT1[218].B
0xE0F6C GLCDC 32-bit
  [31:24] GR2CLUT1[219].A, [23:16] GR2CLUT1[219].R, [15:8] GR2CLUT1[219].G, [7:0] GR2CLUT1[219].B
0xE0F70 GLCDC 32-bit
  [31:24] GR2CLUT1[220].A, [23:16] GR2CLUT1[220].R, [15:8] GR2CLUT1[220].G, [7:0] GR2CLUT1[220].B
0xE0F74 GLCDC 32-bit
  [31:24] GR2CLUT1[221].A, [23:16] GR2CLUT1[221].R, [15:8] GR2CLUT1[221].G, [7:0] GR2CLUT1[221].B
0xE0F78 GLCDC 32-bit
  [31:24] GR2CLUT1[222].A, [23:16] GR2CLUT1[222].R, [15:8] GR2CLUT1[222].G, [7:0] GR2CLUT1[222].B
0xE0F7C GLCDC 32-bit
  [31:24] GR2CLUT1[223].A, [23:16] GR2CLUT1[223].R, [15:8] GR2CLUT1[223].G, [7:0] GR2CLUT1[223].B
0xE0F80 GLCDC 32-bit
  [31:24] GR2CLUT1[224].A, [23:16] GR2CLUT1[224].R, [15:8] GR2CLUT1[224].G, [7:0] GR2CLUT1[224].B
0xE0F84 GLCDC 32-bit
  [31:24] GR2CLUT1[225].A, [23:16] GR2CLUT1[225].R, [15:8] GR2CLUT1[225].G, [7:0] GR2CLUT1[225].B
0xE0F88 GLCDC 32-bit
  [31:24] GR2CLUT1[226].A, [23:16] GR2CLUT1[226].R, [15:8] GR2CLUT1[226].G, [7:0] GR2CLUT1[226].B
0xE0F8C GLCDC 32-bit
  [31:24] GR2CLUT1[227].A, [23:16] GR2CLUT1[227].R, [15:8] GR2CLUT1[227].G, [7:0] GR2CLUT1[227].B
0xE0F90 GLCDC 32-bit
  [31:24] GR2CLUT1[228].A, [23:16] GR2CLUT1[228].R, [15:8] GR2CLUT1[228].G, [7:0] GR2CLUT1[228].B
0xE0F94 GLCDC 32-bit
  [31:24] GR2CLUT1[229].A, [23:16] GR2CLUT1[229].R, [15:8] GR2CLUT1[229].G, [7:0] GR2CLUT1[229].B
0xE0F98 GLCDC 32-bit
  [31:24] GR2CLUT1[230].A, [23:16] GR2CLUT1[230].R, [15:8] GR2CLUT1[230].G, [7:0] GR2CLUT1[230].B
0xE0F9C GLCDC 32-bit
  [31:24] GR2CLUT1[231].A, [23:16] GR2CLUT1[231].R, [15:8] GR2CLUT1[231].G, [7:0] GR2CLUT1[231].B
0xE0FA0 GLCDC 32-bit
  [31:24] GR2CLUT1[232].A, [23:16] GR2CLUT1[232].R, [15:8] GR2CLUT1[232].G, [7:0] GR2CLUT1[232].B
0xE0FA4 GLCDC 32-bit
  [31:24] GR2CLUT1[233].A, [23:16] GR2CLUT1[233].R, [15:8] GR2CLUT1[233].G, [7:0] GR2CLUT1[233].B
0xE0FA8 GLCDC 32-bit
  [31:24] GR2CLUT1[234].A, [23:16] GR2CLUT1[234].R, [15:8] GR2CLUT1[234].G, [7:0] GR2CLUT1[234].B
0xE0FAC GLCDC 32-bit
  [31:24] GR2CLUT1[235].A, [23:16] GR2CLUT1[235].R, [15:8] GR2CLUT1[235].G, [7:0] GR2CLUT1[235].B
0xE0FB0 GLCDC 32-bit
  [31:24] GR2CLUT1[236].A, [23:16] GR2CLUT1[236].R, [15:8] GR2CLUT1[236].G, [7:0] GR2CLUT1[236].B
0xE0FB4 GLCDC 32-bit
  [31:24] GR2CLUT1[237].A, [23:16] GR2CLUT1[237].R, [15:8] GR2CLUT1[237].G, [7:0] GR2CLUT1[237].B
0xE0FB8 GLCDC 32-bit
  [31:24] GR2CLUT1[238].A, [23:16] GR2CLUT1[238].R, [15:8] GR2CLUT1[238].G, [7:0] GR2CLUT1[238].B
0xE0FBC GLCDC 32-bit
  [31:24] GR2CLUT1[239].A, [23:16] GR2CLUT1[239].R, [15:8] GR2CLUT1[239].G, [7:0] GR2CLUT1[239].B
0xE0FC0 GLCDC 32-bit
  [31:24] GR2CLUT1[240].A, [23:16] GR2CLUT1[240].R, [15:8] GR2CLUT1[240].G, [7:0] GR2CLUT1[240].B
0xE0FC4 GLCDC 32-bit
  [31:24] GR2CLUT1[241].A, [23:16] GR2CLUT1[241].R, [15:8] GR2CLUT1[241].G, [7:0] GR2CLUT1[241].B
0xE0FC8 GLCDC 32-bit
  [31:24] GR2CLUT1[242].A, [23:16] GR2CLUT1[242].R, [15:8] GR2CLUT1[242].G, [7:0] GR2CLUT1[242].B
0xE0FCC GLCDC 32-bit
  [31:24] GR2CLUT1[243].A, [23:16] GR2CLUT1[243].R, [15:8] GR2CLUT1[243].G, [7:0] GR2CLUT1[243].B
0xE0FD0 GLCDC 32-bit
  [31:24] GR2CLUT1[244].A, [23:16] GR2CLUT1[244].R, [15:8] GR2CLUT1[244].G, [7:0] GR2CLUT1[244].B
0xE0FD4 GLCDC 32-bit
  [31:24] GR2CLUT1[245].A, [23:16] GR2CLUT1[245].R, [15:8] GR2CLUT1[245].G, [7:0] GR2CLUT1[245].B
0xE0FD8 GLCDC 32-bit
  [31:24] GR2CLUT1[246].A, [23:16] GR2CLUT1[246].R, [15:8] GR2CLUT1[246].G, [7:0] GR2CLUT1[246].B
0xE0FDC GLCDC 32-bit
  [31:24] GR2CLUT1[247].A, [23:16] GR2CLUT1[247].R, [15:8] GR2CLUT1[247].G, [7:0] GR2CLUT1[247].B
0xE0FE0 GLCDC 32-bit
  [31:24] GR2CLUT1[248].A, [23:16] GR2CLUT1[248].R, [15:8] GR2CLUT1[248].G, [7:0] GR2CLUT1[248].B
0xE0FE4 GLCDC 32-bit
  [31:24] GR2CLUT1[249].A, [23:16] GR2CLUT1[249].R, [15:8] GR2CLUT1[249].G, [7:0] GR2CLUT1[249].B
0xE0FE8 GLCDC 32-bit
  [31:24] GR2CLUT1[250].A, [23:16] GR2CLUT1[250].R, [15:8] GR2CLUT1[250].G, [7:0] GR2CLUT1[250].B
0xE0FEC GLCDC 32-bit
  [31:24] GR2CLUT1[251].A, [23:16] GR2CLUT1[251].R, [15:8] GR2CLUT1[251].G, [7:0] GR2CLUT1[251].B
0xE0FF0 GLCDC 32-bit
  [31:24] GR2CLUT1[252].A, [23:16] GR2CLUT1[252].R, [15:8] GR2CLUT1[252].G, [7:0] GR2CLUT1[252].B
0xE0FF4 GLCDC 32-bit
  [31:24] GR2CLUT1[253].A, [23:16] GR2CLUT1[253].R, [15:8] GR2CLUT1[253].G, [7:0] GR2CLUT1[253].B
0xE0FF8 GLCDC 32-bit
  [31:24] GR2CLUT1[254].A, [23:16] GR2CLUT1[254].R, [15:8] GR2CLUT1[254].G, [7:0] GR2CLUT1[254].B
0xE0FFC GLCDC 32-bit
  [31:24] GR2CLUT1[255].A, [23:16] GR2CLUT1[255].R, [15:8] GR2CLUT1[255].G, [7:0] GR2CLUT1[255].B
0xE1000 GLCDC 32-bit
  [16] BGEN.SWRST, [8] BGEN.VEN, [0] BGEN.EN
0xE1004 GLCDC 32-bit
  [26:16] BGPERI.FV, [10:0] BGPERI.FH
0xE1008 GLCDC 32-bit
  [19:16] BGSYNC.VP, [3:0] BGSYNC.HP
0xE100C GLCDC 32-bit
  [26:16] BGVSIZE.VP, [10:0] BGVSIZE.VW
0xE1010 GLCDC 32-bit
  [26:16] BGHSIZE.HP, [10:0] BGHSIZE.HW
0xE1014 GLCDC 32-bit
  [23:16] BGCOLOR.R, [15:8] BGCOLOR.G, [7:0] BGCOLOR.B
0xE1018 GLCDC 32-bit
  [16] BGMON.SWRST, [8] BGMON.VEN, [0] BGMON.EN
0xE1100 GLCDC 32-bit
  [0] GR1VEN.VEN
0xE1104 GLCDC 32-bit
  [0] GR1FLMRD.RENB
0xE1110 GLCDC 32-bit
  [31:16] GR1FLM3.LNOFF
0xE1118 GLCDC 32-bit
  [26:16] GR1FLM5.LNNUM, [15:0] GR1FLM5.DATANUM
0xE111C GLCDC 32-bit
  [30:28] GR1FLM6.FORMAT
0xE1120 GLCDC 32-bit
  [12] GR1AB1.ARCON, [8] GR1AB1.ARCDISPON, [4] GR1AB1.GRCDISPON, [1:0] GR1AB1.DISPSEL
0xE1124 GLCDC 32-bit
  [26:16] GR1AB2.GRCVS, [10:0] GR1AB2.GRCVW
0xE1128 GLCDC 32-bit
  [26:16] GR1AB3.GRCHS, [10:0] GR1AB3.GRCHW
0xE112C GLCDC 32-bit
  [26:16] GR1AB4.ARCVS, [10:0] GR1AB4.ARCVW
0xE1130 GLCDC 32-bit
  [26:16] GR1AB5.ARCHS, [10:0] GR1AB5.ARCHW
0xE1134 GLCDC 32-bit
  [24:16] GR1AB6.ARCCOEF, [7:0] GR1AB6.ARCRATE
0xE1138 GLCDC 32-bit
  [23:16] GR1AB7.ARCDEF, [0] GR1AB7.CKON
0xE113C GLCDC 32-bit
  [23:16] GR1AB8.CKKG, [15:8] GR1AB8.CKKB, [7:0] GR1AB8.CKKR
0xE1140 GLCDC 32-bit
  [31:24] GR1AB9.CKA, [23:16] GR1AB9.CKG, [15:8] GR1AB9.CKB, [7:0] GR1AB9.CKR
0xE114C GLCDC 32-bit
  [23:16] GR1BASE.G, [15:8] GR1BASE.B, [7:0] GR1BASE.R
0xE1150 GLCDC 32-bit
  [16] GR1CLUTINT.SEL, [10:0] GR1CLUTINT.LINE
0xE1154 GLCDC 32-bit
  [16] GR1MON.UFST, [0] GR1MON.ARCST
0xE1200 GLCDC 32-bit
  [0] GR2VEN.VEN
0xE1204 GLCDC 32-bit
  [0] GR2FLMRD.RENB
0xE1210 GLCDC 32-bit
  [31:16] GR2FLM3.LNOFF
0xE1218 GLCDC 32-bit
  [26:16] GR2FLM5.LNNUM, [15:0] GR2FLM5.DATANUM
0xE121C GLCDC 32-bit
  [30:28] GR2FLM6.FORMAT
0xE1220 GLCDC 32-bit
  [12] GR2AB1.ARCON, [8] GR2AB1.ARCDISPON, [4] GR2AB1.GRCDISPON, [1:0] GR2AB1.DISPSEL
0xE1224 GLCDC 32-bit
  [26:16] GR2AB2.GRCVS, [10:0] GR2AB2.GRCVW
0xE1228 GLCDC 32-bit
  [26:16] GR2AB3.GRCHS, [10:0] GR2AB3.GRCHW
0xE122C GLCDC 32-bit
  [26:16] GR2AB4.ARCVS, [10:0] GR2AB4.ARCVW
0xE1230 GLCDC 32-bit
  [26:16] GR2AB5.ARCHS, [10:0] GR2AB5.ARCHW
0xE1234 GLCDC 32-bit
  [24:16] GR2AB6.ARCCOEF, [7:0] GR2AB6.ARCRATE
0xE1238 GLCDC 32-bit
  [23:16] GR2AB7.ARCDEF, [0] GR2AB7.CKON
0xE123C GLCDC 32-bit
  [23:16] GR2AB8.CKKG, [15:8] GR2AB8.CKKB, [7:0] GR2AB8.CKKR
0xE1240 GLCDC 32-bit
  [31:24] GR2AB9.CKA, [23:16] GR2AB9.CKG, [15:8] GR2AB9.CKB, [7:0] GR2AB9.CKR
0xE124C GLCDC 32-bit
  [23:16] GR2BASE.G, [15:8] GR2BASE.B, [7:0] GR2BASE.R
0xE1250 GLCDC 32-bit
  [16] GR2CLUTINT.SEL, [10:0] GR2CLUTINT.LINE
0xE1254 GLCDC 32-bit
  [16] GR2MON.UFST, [0] GR2MON.ARCST
0xE1300 GLCDC 32-bit
  [0] GAMGVEN.VEN
0xE1304 GLCDC 32-bit
  [0] GAMSW.GAMON
0xE1308 GLCDC 32-bit
  [26:16] GAMGLUT1.GAIN00, [10:0] GAMGLUT1.GAIN01
0xE130C GLCDC 32-bit
  [26:16] GAMGLUT2.GAIN02, [10:0] GAMGLUT2.GAIN03
0xE1310 GLCDC 32-bit
  [26:16] GAMGLUT3.GAIN04, [10:0] GAMGLUT3.GAIN05
0xE1314 GLCDC 32-bit
  [26:16] GAMGLUT4.GAIN06, [10:0] GAMGLUT4.GAIN07
0xE1318 GLCDC 32-bit
  [26:16] GAMGLUT5.GAIN08, [10:0] GAMGLUT5.GAIN09
0xE131C GLCDC 32-bit
  [26:16] GAMGLUT6.GAIN10, [10:0] GAMGLUT6.GAIN11
0xE1320 GLCDC 32-bit
  [26:16] GAMGLUT7.GAIN12, [10:0] GAMGLUT7.GAIN13
0xE1324 GLCDC 32-bit
  [26:16] GAMGLUT8.GAIN14, [10:0] GAMGLUT8.GAIN15
0xE1328 GLCDC 32-bit
  [29:20] GAMGAREA1.TH01, [19:10] GAMGAREA1.TH02, [9:0] GAMGAREA1.TH03
0xE132C GLCDC 32-bit
  [29:20] GAMGAREA2.TH04, [19:10] GAMGAREA2.TH05, [9:0] GAMGAREA2.TH06
0xE1330 GLCDC 32-bit
  [29:20] GAMGAREA3.TH07, [19:10] GAMGAREA3.TH08, [9:0] GAMGAREA3.TH09
0xE1334 GLCDC 32-bit
  [29:20] GAMGAREA4.TH10, [19:10] GAMGAREA4.TH11, [9:0] GAMGAREA4.TH12
0xE1338 GLCDC 32-bit
  [29:20] GAMGAREA5.TH13, [19:10] GAMGAREA5.TH14, [9:0] GAMGAREA5.TH15
0xE1340 GLCDC 32-bit
  [0] GAMBVEN.VEN
0xE1348 GLCDC 32-bit
  [26:16] GAMBLUT1.GAIN00, [10:0] GAMBLUT1.GAIN01
0xE134C GLCDC 32-bit
  [26:16] GAMBLUT2.GAIN02, [10:0] GAMBLUT2.GAIN03
0xE1350 GLCDC 32-bit
  [26:16] GAMBLUT3.GAIN04, [10:0] GAMBLUT3.GAIN05
0xE1354 GLCDC 32-bit
  [26:16] GAMBLUT4.GAIN06, [10:0] GAMBLUT4.GAIN07
0xE1358 GLCDC 32-bit
  [26:16] GAMBLUT5.GAIN08, [10:0] GAMBLUT5.GAIN09
0xE135C GLCDC 32-bit
  [26:16] GAMBLUT6.GAIN10, [10:0] GAMBLUT6.GAIN11
0xE1360 GLCDC 32-bit
  [26:16] GAMBLUT7.GAIN12, [10:0] GAMBLUT7.GAIN13
0xE1364 GLCDC 32-bit
  [26:16] GAMBLUT8.GAIN14, [10:0] GAMBLUT8.GAIN15
0xE1368 GLCDC 32-bit
  [29:20] GAMBAREA1.TH01, [19:10] GAMBAREA1.TH02, [9:0] GAMBAREA1.TH03
0xE136C GLCDC 32-bit
  [29:20] GAMBAREA2.TH04, [19:10] GAMBAREA2.TH05, [9:0] GAMBAREA2.TH06
0xE1370 GLCDC 32-bit
  [29:20] GAMBAREA3.TH07, [19:10] GAMBAREA3.TH08, [9:0] GAMBAREA3.TH09
0xE1374 GLCDC 32-bit
  [29:20] GAMBAREA4.TH10, [19:10] GAMBAREA4.TH11, [9:0] GAMBAREA4.TH12
0xE1378 GLCDC 32-bit
  [29:20] GAMBAREA5.TH13, [19:10] GAMBAREA5.TH14, [9:0] GAMBAREA5.TH15
0xE1380 GLCDC 32-bit
  [0] GAMRVEN.VEN
0xE1388 GLCDC 32-bit
  [26:16] GAMRLUT1.GAIN00, [10:0] GAMRLUT1.GAIN01
0xE138C GLCDC 32-bit
  [26:16] GAMRLUT2.GAIN02, [10:0] GAMRLUT2.GAIN03
0xE1390 GLCDC 32-bit
  [26:16] GAMRLUT3.GAIN04, [10:0] GAMRLUT3.GAIN05
0xE1394 GLCDC 32-bit
  [26:16] GAMRLUT4.GAIN06, [10:0] GAMRLUT4.GAIN07
0xE1398 GLCDC 32-bit
  [26:16] GAMRLUT5.GAIN08, [10:0] GAMRLUT5.GAIN09
0xE139C GLCDC 32-bit
  [26:16] GAMRLUT6.GAIN10, [10:0] GAMRLUT6.GAIN11
0xE13A0 GLCDC 32-bit
  [26:16] GAMRLUT7.GAIN12, [10:0] GAMRLUT7.GAIN13
0xE13A4 GLCDC 32-bit
  [26:16] GAMRLUT8.GAIN14, [10:0] GAMRLUT8.GAIN15
0xE13A8 GLCDC 32-bit
  [29:20] GAMRAREA1.TH01, [19:10] GAMRAREA1.TH02, [9:0] GAMRAREA1.TH03
0xE13AC GLCDC 32-bit
  [29:20] GAMRAREA2.TH04, [19:10] GAMRAREA2.TH05, [9:0] GAMRAREA2.TH06
0xE13B0 GLCDC 32-bit
  [29:20] GAMRAREA3.TH07, [19:10] GAMRAREA3.TH08, [9:0] GAMRAREA3.TH09
0xE13B4 GLCDC 32-bit
  [29:20] GAMRAREA4.TH10, [19:10] GAMRAREA4.TH11, [9:0] GAMRAREA4.TH12
0xE13B8 GLCDC 32-bit
  [29:20] GAMRAREA5.TH13, [19:10] GAMRAREA5.TH14, [9:0] GAMRAREA5.TH15
0xE13C0 GLCDC 32-bit
  [0] OUTVEN.VEN
0xE13C4 GLCDC 32-bit
  [28] OUTSET.ENDIANON, [24] OUTSET.SWAPON, [13:12] OUTSET.FORMAT, [9] OUTSET.FRQSEL, [4] OUTSET.DIRSEL, [1:0] OUTSET.PHASE
0xE13C8 GLCDC 32-bit
  [9:0] BRIGHT1.BRTG
0xE13CC GLCDC 32-bit
  [25:16] BRIGHT2.BRTB, [9:0] BRIGHT2.BRTR
0xE13D0 GLCDC 32-bit
  [23:16] CONTRAST.CONTG, [15:8] CONTRAST.CONTB, [7:0] CONTRAST.CONTR
0xE13D4 GLCDC 32-bit
  [21:20] PANELDTHA.SEL, [17:16] PANELDTHA.FORM, [13:12] PANELDTHA.PA, [9:8] PANELDTHA.PB, [5:4] PANELDTHA.PC, [1:0] PANELDTHA.PD
0xE13E4 GLCDC 32-bit
  [12] CLKPHASE.FRONTGAM, [8] CLKPHASE.LCDEDG, [6-n] CLKPHASE.TCON{n}EDG (n=0..3)
0xE1404 GLCDC 32-bit
  [26:16] TCONTIM.HALF, [10:0] TCONTIM.OFFSET
0xE1408 GLCDC 32-bit
  [26:16] TCONSTVA1.VS, [10:0] TCONSTVA1.VW
0xE140C GLCDC 32-bit
  [4] TCONSTVA2.INV, [2:0] TCONSTVA2.SEL
0xE1410 GLCDC 32-bit
  [26:16] TCONSTVB1.VS, [10:0] TCONSTVB1.VW
0xE1414 GLCDC 32-bit
  [4] TCONSTVB2.INV, [2:0] TCONSTVB2.SEL
0xE1418 GLCDC 32-bit
  [26:16] TCONSTHA1.HS, [10:0] TCONSTHA1.HW
0xE141C GLCDC 32-bit
  [8] TCONSTHA2.HSSEL, [4] TCONSTHA2.INV, [2:0] TCONSTHA2.SEL
0xE1420 GLCDC 32-bit
  [26:16] TCONSTHB1.HS, [10:0] TCONSTHB1.HW
0xE1424 GLCDC 32-bit
  [8] TCONSTHB2.HSSEL, [4] TCONSTHB2.INV, [2:0] TCONSTHB2.SEL
0xE1428 GLCDC 32-bit
  [0] TCONDE.INV
0xE1440 GLCDC 32-bit
  [2] DTCTEN.GR2UFDTC, [1] DTCTEN.GR1UFDTC, [0] DTCTEN.VPOSDTC
0xE1444 GLCDC 32-bit
  [2] INTEN.GR2UFINTEN, [1] INTEN.GR1UFINTEN, [0] INTEN.VPOSINTEN
0xE1448 GLCDC 32-bit
  [2] STCLR.GR2UFCLR, [1] STCLR.GR1UFCLR, [0] STCLR.VPOSCLR
0xE144C GLCDC 32-bit
  [2] STMON.GR2UF, [1] STMON.GR1UF, [0] STMON.VPOS
0xE1450 GLCDC 32-bit
  [12] PANELCLK.PIXSEL, [8] PANELCLK.CLKSEL, [6] PANELCLK.CLKEN, [5:0] PANELCLK.DCDR
0xE3000 DRW2D 32-bit
  [23] CONTROL.SPANSTR, [22] CONTROL.SPANABT, [21] CONTROL.UNIONCD, [20] CONTROL.UNIONAB, [19] CONTROL.UNION56, [18] CONTROL.UNION34, [17] CONTROL.UNION12, [16] CONTROL.BAND2EN, [15] CONTROL.BAND1EN, [n+8] CONTROL.LIM{n}TH (n=1..6), [8] CONTROL.QUAD3EN, [7] CONTROL.QUAD2EN, [6] CONTROL.QUAD1EN, [n-1] CONTROL.LIM{n}EN (n=1..6), [5] STATUS.DLIR, [4] STATUS.ENUIR, [3] STATUS.DLSTACT, [2] STATUS.CACHEDTY, [1] STATUS.BSYWR, [0] STATUS.BSYENUM
0xE3004 DRW2D 32-bit
  [31:30] CONTROL2.RLEPIXW, [29] CONTROL2.BDIA, [28] CONTROL2.BSIA, [27] CONTROL2.CLUTFORM, [27] HWVER.ACBLD, [26] CONTROL2.COLKEYEN, [25] CONTROL2.CLUTEN, [25] HWVER.COLKEY, [24] CONTROL2.RLEEN, [24] HWVER.TEXCLUT256, [23] HWVER.RLEUNIT, [23:22] CONTROL2.WRALPHA, [21] HWVER.TEXCLUT, [21:20] CONTROL2.WRFMT, [20] HWVER.PERFCNT, [19] HWVER.TXCACHE, [19:18] CONTROL2.RDFMT, [18] HWVER.FBCACHE, [17] CONTROL2.TEXFILTY, [17] HWVER.DLR, [16] CONTROL2.TEXFILTX, [15] CONTROL2.TEXCLPY, [14] CONTROL2.TEXCLPX, [13] CONTROL2.BC2, [12] CONTROL2.BDI, [11] CONTROL2.BSI, [10] CONTROL2.BDF, [9] CONTROL2.BSF, [8] CONTROL2.WRFMT2, [7] CONTROL2.BDFA, [6] CONTROL2.BSFA, [5:4] CONTROL2.RDFMT2, [3] CONTROL2.USEACB, [2] CONTROL2.PTNSRCL5, [1] CONTROL2.TEXENA, [0] CONTROL2.PTNEN, [11:0] HWVER.REV
0xE3064 DRW2D 32-bit
  [31:24] COLOR1.COL1A, [23:16] COLOR1.COL1R, [15:8] COLOR1.COL1G, [7:0] COLOR1.COL1B
0xE3068 DRW2D 32-bit
  [31:24] COLOR2.COL2A, [23:16] COLOR2.COL2R, [15:8] COLOR2.COL2G, [7:0] COLOR2.COL2B
0xE3078 DRW2D 32-bit
  [31:16] SIZE.Y, [15:0] SIZE.X
0xE307C DRW2D 32-bit
  [31:16] PITCH.SSD, [15:0] PITCH.PITCH
0xE30AC DRW2D 32-bit
  [31:16] LVYXADDF.LVYADDF, [15:0] LVYXADDF.LVXADDF
0xE30B8 DRW2D 32-bit
  [31:11] TEXMSK.TEXVMSK, [10:0] TEXMSK.TEXUMSK
0xE30C0 DRW2D 32-bit
  [3] IRQCTL.DLIRCLR, [2] IRQCTL.ENUIRCLR, [1] IRQCTL.DLIREN, [0] IRQCTL.ENUIREN
0xE30C4 DRW2D 32-bit
  [3] CACHECTL.CFLUTX, [2] CACHECTL.CENTX, [1] CACHECTL.CFLUFX, [0] CACHECTL.CENFX
0xE30D4 DRW2D 32-bit
  [31:16] PERFTRG.TRG2, [15:0] PERFTRG.TRG1
0xE30E8 DRW2D 32-bit
  [23:16] COLKEY.R, [15:8] COLKEY.G, [7:0] COLKEY.B
0x7FE010 FLASH
  [7] FASTAT.CFAE, [4] FASTAT.CMDLK, [3] FASTAT.DFAE
0x7FE014 FLASH
  [7] FAEINT.CFAEIE, [4] FAEINT.CMDLKIE, [3] FAEINT.DFAEIE
0x7FE018 FLASH
  [0] FRDYIE.FRDYIE
0x7FE030 FLASH 32-bit
  [31:0] FSADDR.FSADDR
0x7FE034 FLASH 32-bit
  [31:0] FEADDR.FEADDR
0x7FE080 FLASH 32-bit
  [23] FSTATR.ILGCOMERR, [22] FSTATR.FESETERR, [21] FSTATR.SECERR, [20] FSTATR.OTERR, [15] FSTATR.FRDY, [14] FSTATR.ILGLERR, [13] FSTATR.ERSERR, [12] FSTATR.PRGERR, [11] FSTATR.SUSRDY, [10] FSTATR.DBFULL, [9] FSTATR.ERSSPD, [8] FSTATR.PRGSPD, [6] FSTATR.FLWEERR
0x7FE084 FLASH 16-bit
  [15:8] FENTRYR.KEY, [7] FENTRYR.FENTRYD, [0] FENTRYR.FENTRYC
0x7FE08C FLASH 16-bit
  [15:8] FSUINITR.KEY, [0] FSUINITR.SUINIT
0x7FE0A0 FLASH 16-bit
  [15:8] FCMDR.CMDR, [7:0] FCMDR.PCMDR
0x7FE0D0 FLASH
  [0] FBCCNT.BCDIR
0x7FE0D4 FLASH
  [0] FBCSTAT.BCST
0x7FE0D8 FLASH 32-bit
  [18:0] FPSADDR.PSADR
0x7FE0DC FLASH 32-bit
  [31] FAWMON.BTFLG, [27:16] FAWMON.FAWE, [15] FAWMON.FSPR, [11:0] FAWMON.FAWS
0x7FE0E0 FLASH 16-bit
  [0] FCPSR.ESUSPMD
0x7FE0E4 FLASH 16-bit
  [15:8] FPCKAR.KEY, [7:0] FPCKAR.PCKA
0x7FE0E8 FLASH 16-bit
  [15:8] FSUACR.KEY, [1:0] FSUACR.SAS
